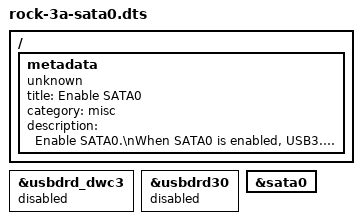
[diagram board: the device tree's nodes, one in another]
// ROCK 3A usb3.0 otg port to sata
/dts-v1/;
/plugin/;

/ {
	metadata {
		title = "Enable SATA0";
		compatible = "unknown";
		category = "misc";
		description = "Enable SATA0.\nWhen SATA0 is enabled, USB3.0 cannot be enabled on the same port.";
	};

	fragment@0 {
		target = <&usbdrd_dwc3>;

		__overlay__ {
			status = "disabled";
		};
	};

	fragment@1 {
		target = <&usbdrd30>;

		__overlay__ {
			status = "disabled";
		};
	};

	fragment@2 {
		target = <&sata0>;

		__overlay__ {
			status = "okay";
		};
	};
};
